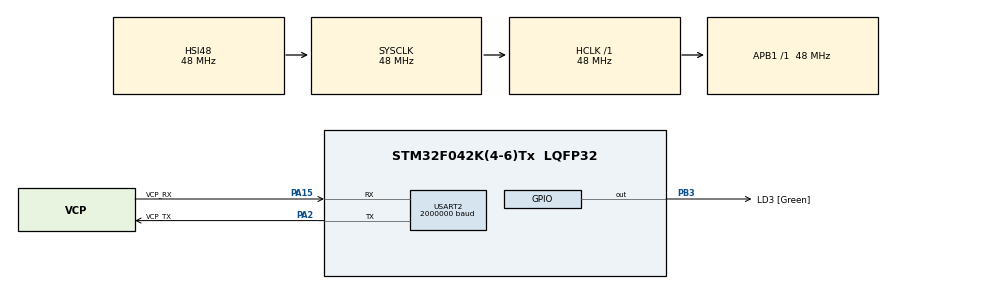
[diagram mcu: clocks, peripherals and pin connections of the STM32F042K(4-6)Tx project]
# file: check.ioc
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FREERTOS.Tasks01=defaultTask,0,64,StartDefaultTask,Default,NULL,Dynamic,NULL,NULL
FREERTOS.configMINIMAL_STACK_SIZE=64
IWDG.Prescaler=IWDG_PRESCALER_32
Mcu.Family=STM32F0
Mcu.Name=STM32F042K(4-6)Tx
Mcu.Package=LQFP32
NVIC.USART2_IRQn=true\:3\:0\:false\:false\:true\:true\:true
PA13.GPIO_Label=SWDIO
PA13.Mode=Serial_Wire
PA13.Signal=SYS_SWDIO
PA14.GPIO_Label=SWCLK
PA14.Mode=Serial_Wire
PA14.Signal=SYS_SWCLK
PA15.GPIO_Label=VCP_RX
PA15.Mode=Asynchronous
PA15.Signal=USART2_RX
PA2.GPIO_Label=VCP_TX
PA2.Mode=Asynchronous
PA2.Signal=USART2_TX
PB3.GPIO_Label=LD3 [Green]
PB3.Signal=GPIO_Output
PF0-OSC_IN.GPIO_Label=MCO
PF0-OSC_IN.Signal=RCC_OSC_IN
ProjectManager.HeapSize=0x200
ProjectManager.StackSize=0x400
ProjectManager.TargetToolchain=MDK-ARM V5
RCC.AHBFreq_Value=48000000
RCC.APB1Freq_Value=48000000
RCC.APB1TimFreq_Value=48000000
RCC.HCLKFreq_Value=48000000
RCC.PLLMUL=RCC_PLL_MUL6
RCC.SYSCLKFreq_VALUE=48000000
RCC.SYSCLKSource=RCC_SYSCLKSOURCE_HSI48
USART2.BaudRate=2000000
USART2.VirtualMode-Asynchronous=VM_ASYNC
VP_FREERTOS_VS_ENABLE.Mode=Enabled
VP_IWDG_VS_IWDG.Mode=IWDG_Activate
board=NUCLEO-F042K6

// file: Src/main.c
/**
  ******************************************************************************
  * @file           : main.c
  * @brief          : Main program body
  ******************************************************************************
  * This notice applies to any and all portions of this file
  * that are not between comment pairs USER CODE BEGIN and
  * USER CODE END. Other portions of this file, whether
  * inserted by the user or by software development tools
  * are owned by their respective copyright owners.
  *
  * Copyright (c) 2018 STMicroelectronics International N.V.
  * All rights reserved.
  *
  * Redistribution and use in source and binary forms, with or without
  * modification, are permitted, provided that the following conditions are met:
  *
  * 1. Redistribution of source code must retain the above copyright notice,
  *    this list of conditions and the following disclaimer.
  * 2. Redistributions in binary form must reproduce the above copyright notice,
  *    this list of conditions and the following disclaimer in the documentation
  *    and/or other materials provided with the distribution.
  * 3. Neither the name of STMicroelectronics nor the names of other
  *    contributors to this software may be used to endorse or promote products
  *    derived from this software without specific written permission.
  * 4. This software, including modifications and/or derivative works of this
  *    software, must execute solely and exclusively on microcontroller or
  *    microprocessor devices manufactured by or for STMicroelectronics.
  * 5. Redistribution and use of this software other than as permitted under
  *    this license is void and will automatically terminate your rights under
  *    this license.
  *
  * THIS SOFTWARE IS PROVIDED BY STMICROELECTRONICS AND CONTRIBUTORS "AS IS"
  * AND ANY EXPRESS, IMPLIED OR STATUTORY WARRANTIES, INCLUDING, BUT NOT
  * LIMITED TO, THE IMPLIED WARRANTIES OF MERCHANTABILITY, FITNESS FOR A
  * PARTICULAR PURPOSE AND NON-INFRINGEMENT OF THIRD PARTY INTELLECTUAL PROPERTY
  * RIGHTS ARE DISCLAIMED TO THE FULLEST EXTENT PERMITTED BY LAW. IN NO EVENT
  * SHALL STMICROELECTRONICS OR CONTRIBUTORS BE LIABLE FOR ANY DIRECT, INDIRECT,
  * INCIDENTAL, SPECIAL, EXEMPLARY, OR CONSEQUENTIAL DAMAGES (INCLUDING, BUT NOT
  * LIMITED TO, PROCUREMENT OF SUBSTITUTE GOODS OR SERVICES; LOSS OF USE, DATA,
  * OR PROFITS; OR BUSINESS INTERRUPTION) HOWEVER CAUSED AND ON ANY THEORY OF
  * LIABILITY, WHETHER IN CONTRACT, STRICT LIABILITY, OR TORT (INCLUDING
  * NEGLIGENCE OR OTHERWISE) ARISING IN ANY WAY OUT OF THE USE OF THIS SOFTWARE,
  * EVEN IF ADVISED OF THE POSSIBILITY OF SUCH DAMAGE.
  *
  ******************************************************************************
  */
#include "main.h"
#include "stm32f0xx_hal.h"
#include "cmsis_os.h"

IWDG_HandleTypeDef hiwdg;

UART_HandleTypeDef huart2;

osThreadId defaultTaskHandle;

/* USER CODE BEGIN PV */
/* Private variables ---------------------------------------------------------*/
uint8_t DATA[3]={0xAA,0xBB,0xCC};
#define ADDR_FLASH_PAGE_30    ((uint32_t)0x08007800) /* Base @ of Page 30, 1 Kbyte */				//	需要将CAN地址保存的地址
#define	Reload_value_IWDG_ADDR 0x08007800
#define Reload_value_IWDG_ADDR_FLASH_PAGE ((uint32_t)Reload_value_IWDG_ADDR)
#define Reload_value_IWDG_ADDR_FLASH_PAGE_end ((uint32_t)(Reload_value_IWDG_ADDR+0x400))
/* Private macro -------------------------------------------------------------*/
/* Private variables ---------------------------------------------------------*/
uint32_t Address = 0, PAGEError = 0;
__IO uint32_t data32 = 0 , MemoryProgramStatus = 0;
/*Variable used for Erase procedure*/
static FLASH_EraseInitTypeDef EraseInitStruct;
uint32_t DATA_32=0x12345678;							//	写到FLASH中的全局变量
void CAN_ID_update(void);
uint8_t Reload_value_IWDG_byte[2];
/* USER CODE END PV */

void SystemClock_Config(void);
static void MX_GPIO_Init(void);
static void MX_USART2_UART_Init(void);
static void MX_IWDG_Init(void);
void StartDefaultTask(void const * argument);

/* USER CODE BEGIN PFP */
/* Private function prototypes -----------------------------------------------*/

/* USER CODE END PFP */

int main(void)
{

  /* MCU Configuration----------------------------------------------------------*/

  /* Reset of all peripherals, Initializes the Flash interface and the Systick. */
  HAL_Init();

  /* Configure the system clock */
  SystemClock_Config();

  /* Initialize all configured peripherals */
  MX_GPIO_Init();
  MX_USART2_UART_Init();
  MX_IWDG_Init();

  /* Create the thread(s) */
  /* definition and creation of defaultTask */
  osThreadDef(defaultTask, StartDefaultTask, osPriorityNormal, 0, 64);
  defaultTaskHandle = osThreadCreate(osThread(defaultTask), NULL);

  /* Start scheduler */
  osKernelStart();

  /* We should never get here as control is now taken by the scheduler */

  /* Infinite loop */
  while (1)
  {

  }

}

void SystemClock_Config(void)
{

  RCC_OscInitTypeDef RCC_OscInitStruct;
  RCC_ClkInitTypeDef RCC_ClkInitStruct;

    /**Initializes the CPU, AHB and APB busses clocks
    */
  RCC_OscInitStruct.OscillatorType = RCC_OSCILLATORTYPE_HSI48|RCC_OSCILLATORTYPE_LSI;
  RCC_OscInitStruct.HSI48State = RCC_HSI48_ON;
  RCC_OscInitStruct.LSIState = RCC_LSI_ON;
  RCC_OscInitStruct.PLL.PLLState = RCC_PLL_NONE;
  if (HAL_RCC_OscConfig(&RCC_OscInitStruct) != HAL_OK)
  {
    _Error_Handler(__FILE__, __LINE__);
  }

    /**Initializes the CPU, AHB and APB busses clocks
    */
  RCC_ClkInitStruct.ClockType = RCC_CLOCKTYPE_HCLK|RCC_CLOCKTYPE_SYSCLK
                              |RCC_CLOCKTYPE_PCLK1;
  RCC_ClkInitStruct.SYSCLKSource = RCC_SYSCLKSOURCE_HSI48;
  RCC_ClkInitStruct.AHBCLKDivider = RCC_SYSCLK_DIV1;
  RCC_ClkInitStruct.APB1CLKDivider = RCC_HCLK_DIV1;

  if (HAL_RCC_ClockConfig(&RCC_ClkInitStruct, FLASH_LATENCY_1) != HAL_OK)
  {
    _Error_Handler(__FILE__, __LINE__);
  }

    /**Configure the Systick interrupt time
    */
  HAL_SYSTICK_Config(HAL_RCC_GetHCLKFreq()/1000);

    /**Configure the Systick
    */
  HAL_SYSTICK_CLKSourceConfig(SYSTICK_CLKSOURCE_HCLK);

  /* SysTick_IRQn interrupt configuration */
  HAL_NVIC_SetPriority(SysTick_IRQn, 3, 0);
}

/* IWDG init function */
static void MX_IWDG_Init(void)
{

  hiwdg.Instance = IWDG;
  hiwdg.Init.Prescaler = IWDG_PRESCALER_32;
  hiwdg.Init.Window = 4095;
  hiwdg.Init.Reload = 4095;
//  if (HAL_IWDG_Init(&hiwdg) != HAL_OK)
//  {
//    _Error_Handler(__FILE__, __LINE__);
//  }

}

/* USART2 init function */
static void MX_USART2_UART_Init(void)
{

  huart2.Instance = USART2;
  huart2.Init.BaudRate = 2000000;
  huart2.Init.WordLength = UART_WORDLENGTH_8B;
  huart2.Init.StopBits = UART_STOPBITS_1;
  huart2.Init.Parity = UART_PARITY_NONE;
  huart2.Init.Mode = UART_MODE_TX_RX;
  huart2.Init.HwFlowCtl = UART_HWCONTROL_NONE;
  huart2.Init.OverSampling = UART_OVERSAMPLING_16;
  huart2.Init.OneBitSampling = UART_ONE_BIT_SAMPLE_DISABLE;
  huart2.AdvancedInit.AdvFeatureInit = UART_ADVFEATURE_NO_INIT;
  if (HAL_UART_Init(&huart2) != HAL_OK)
  {
    _Error_Handler(__FILE__, __LINE__);
  }

}

/** Configure pins as
        * Analog
        * Input
        * Output
        * EVENT_OUT
        * EXTI
*/
static void MX_GPIO_Init(void)
{

  GPIO_InitTypeDef GPIO_InitStruct;

  /* GPIO Ports Clock Enable */
  __HAL_RCC_GPIOF_CLK_ENABLE();
  __HAL_RCC_GPIOA_CLK_ENABLE();
  __HAL_RCC_GPIOB_CLK_ENABLE();

  /*Configure GPIO pin Output Level */
  HAL_GPIO_WritePin(LD3_GPIO_Port, LD3_Pin, GPIO_PIN_RESET);

  /*Configure GPIO pin : LD3_Pin */
  GPIO_InitStruct.Pin = LD3_Pin;
  GPIO_InitStruct.Mode = GPIO_MODE_OUTPUT_PP;
  GPIO_InitStruct.Pull = GPIO_NOPULL;
  GPIO_InitStruct.Speed = GPIO_SPEED_FREQ_LOW;
  HAL_GPIO_Init(LD3_GPIO_Port, &GPIO_InitStruct);

}

/* USER CODE BEGIN 4 */
void CAN_ID_update(void)
{

	DATA_32=0;
	DATA_32=0x12345678;
  /* Unlock the Flash to enable the flash control register access *************/
  HAL_FLASH_Unlock();

  /* Erase the user Flash area
    (area defined by FLASH_USER_START_ADDR and FLASH_USER_END_ADDR) ***********/

  /* Fill EraseInit structure*/
  EraseInitStruct.TypeErase   = FLASH_TYPEERASE_PAGES;
  EraseInitStruct.PageAddress = Reload_value_IWDG_ADDR_FLASH_PAGE;
  EraseInitStruct.NbPages     = (Reload_value_IWDG_ADDR_FLASH_PAGE_end - Reload_value_IWDG_ADDR_FLASH_PAGE) / FLASH_PAGE_SIZE;

	HAL_FLASHEx_Erase(&EraseInitStruct, &PAGEError);
	Address = Reload_value_IWDG_ADDR_FLASH_PAGE;
	HAL_FLASH_Program(FLASH_TYPEPROGRAM_WORD, Address, DATA_32);

  /* Lock the Flash to disable the flash control register access (recommended
     to protect the FLASH memory against possible unwanted operation) *********/
  HAL_FLASH_Lock();

  /* Check if the programmed data is OK
      MemoryProgramStatus = 0: data programmed correctly
      MemoryProgramStatus != 0: number of words not programmed correctly ******/

}
/* USER CODE END 4 */

void StartDefaultTask(void const * argument)
{

  /* USER CODE BEGIN 5 */
//	CAN_ID_update();
	uint8_t Start_DATA[2]={0xFF,0xFF};
	HAL_UART_Transmit(&huart2,Start_DATA,2,10);
	Reload_value_IWDG_byte[0]=*(unsigned int *)Reload_value_IWDG_ADDR;
	Reload_value_IWDG_byte[1]=*(unsigned int *)(Reload_value_IWDG_ADDR+1);
	HAL_UART_Transmit(&huart2,Reload_value_IWDG_byte,2,10);
  /* Infinite loop */
  for(;;)
  {
    osDelay(500);
		HAL_IWDG_Refresh(&hiwdg);
		HAL_GPIO_TogglePin(LD3_GPIO_Port,LD3_Pin);
		HAL_UART_Transmit(&huart2,DATA,3,10);
  }
  /* USER CODE END 5 */
}

void _Error_Handler(char *file, int line)
{
  while(1)
  {
  }
}

/************************ (C) COPYRIGHT STMicroelectronics *****END OF FILE****/
